# RK3399-AP register map
File version: 1
CPU: CA7 r0p1, little endian, MPU, FPU, I-cache, D-cache, VTOR, 4 interrupt priority bits, 0 interrupts
Registers are 32-bit, read-write, reset 0x0 unless marked. A register's access mark holds for its fields unless they carry their own. Offsets are from the block's base; [hi:lo] are bit positions; {n}, {i} and the like mark numbered series.

## EMMCCORE (part 1 of 2)
Base 0xFE330000
0x00 EMMCCORE_SADDR — System address/ Argument 2register/System address/ Argument 2 register
  [31:0] SADDR — This register contains the physical system memory address used for DMA transfers or the second argument for the Auto CMD23. (1) SDMA System Address This register contains the system memory address for a SDMA transfer. When the Host Controller stops a SDMA transfer, this register shall point to the system address of the next contiguous data position. It can be accessed only if no transaction is executing (i.e., after a transaction has stopped). Read operations during transfers may return an invalid value. The Host Driver shall initialize this register before starting a SDMA transaction. After SDMA has stopped, the next system address of the next contiguous data position can be read from this register. The SDMA transfer waits at the every boundary specified by the Host SDMA Buffer Boundary in the Block Size register. The Host Controller generates DMA Interrupt to request the Host Driver to update this register. The Host Driver sets the next system address of the next data position to this register. When the most upper byte of this register (003h) is written, the Host Controller restarts the SDMA transfer. When restarting SDMA by the Resume command or by setting Continue Request in the Block Gap Control register, the Host Controller shall start at the next contiguous address stored here in the SDMA System Address register. ADMA does not use this register. (2) Argument 2 This register is used with the Auto CMD23 to set a 32-bit block count value to the argument of the CMD23 while executing Auto CMD23. If Auto CMD23 is used with ADMA, the full 32-bit block count value can be used. If Auto CMD23 is used without AMDA, the available block count value is limited by the Block Count register. 65535 blocks is the maximum value in this case.
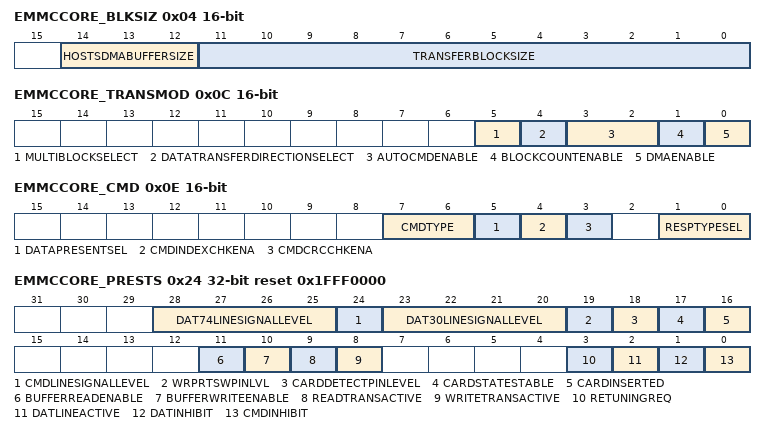
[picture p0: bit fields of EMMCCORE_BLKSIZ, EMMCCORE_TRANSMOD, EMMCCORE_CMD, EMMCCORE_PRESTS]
0x04 EMMCCORE_BLKSIZ 16-bit — Block size register
  [14:12] HOSTSDMABUFFERSIZE — To perform long DMA transfer, System Address register shall be updated at every system boundary during DMA transfer. These bits specify the size of contiguous buffer in the system memory. The DMA transfer shall wait at the every boundary specified by these fields and the HC generates the DMA Interrupt to request the HD to update the System Address register. These bits shall support when the DMA Support in the Capabilities register is set to 1 and this function is active when the DMA Enable in the Transfer Mode register is set to 1. 3\'h0: 4KB(Detects A11 Carry out) 3\'h1: 8KB(Detects A12 Carry out) 3\'h2: 16KB(Detects A13 Carry out) 3\'h3: 32KB(Detects A14 Carry out) 3\'h4: 64KB(Detects A15 Carry out) 3\'h5: 128KB(Detects A16 Carry out) 3\'h6: 256KB(Detects A17 Carry out) 3\'h7: 512KB(Detects A18 Carry out)
  [11:0] TRANSFERBLOCKSIZE — This register specifies the block size for block data transfers for CMD17, CMD18, CMD24, CMD25, and CMD53. It can be accessed only if no transaction is executing (i.e after a transaction has stopped). Read operations during transfer return an invalid value and write operations shall be ignored. 12\'h0000: No Data Transfer 12\'h0001: 1 Byte 12\'h0002: 2 Bytes 12\'h0003: 3 Bytes 12\'h0004: 4 Bytes ........ 12\'h01FF: 511 Bytes 12\'h0200: 512 Bytes ........ 12\'h0800: 2048 Bytes
0x06 EMMCCORE_BLKCNT 16-bit — Block count register
  [15:0] BLOCKCOUNTFORCURRENTTRANSFER — This register is enabled when Block Count Enable in the Transfer Mode register is set to 1 and is valid only for multiple block transfers. The HC decrements the block count after each block transfer and stops when the count reaches zero. It can be accessed only if no transaction is executing (i.e. after a transaction has stopped). Read operations during transfer return an invalid value and write operations shall be ignored. When saving transfer context as a result of Suspend command, the number of blocks yet to be transferred can be determined by reading this register. When restoring transfer context prior to issuing a Resume command, the HD shall restore the previously save block count. 16\'h0000: Stop Count 16\'h0001: 1 block 16\'h0002: 2 blocks ........ 16\'hFFFF: 65535 blocks
0x08 EMMCCORE_ARG — Argument register
  [31:0] COMMANDARGUMENT1 — The SD Command Argument is specified as bit39-8 of Command- Format.
0x0C EMMCCORE_TRANSMOD 16-bit — Transfer mode register
  [5] MULTIBLOCKSELECT — This bit enables multiple block data transfers. 0: Single Block 1: Multiple Block
  [4] DATATRANSFERDIRECTIONSELECT — This bit defines the direction of data transfers. 0: Write (Host to Card) 1: Read (Card to Host)
  [3:2] AUTOCMDENABLE — This field determines use of auto command functions 0: Auto Command Disabled 1: Auto CMD12 Enable 2: Auto CMD23 Enable 3: Reserved There are two methods to stop Multiple-block read and write operation. (1) Auto CMD12 Enable Multiple-block read and write commands for memory require CMD12 to stop the operation. When this field is set to 01b, the Host Controller issues CMD12 automatically when last block transferis completed. Auto CMD12 error is indicated to the Auto CMD Error Status register. The Host Driver shall not set this bit if the command does not require CMD12. (2) Auto CMD23 Enable When this bit field is set to 10b, the Host Controller issues a CMD23 automatically before issuing a command specified in the Command Register The following conditions are required to use the Auto CMD23. a. Auto CMD23 Supported (Host Controller Version is 3.00 or later) b. A memory card that supports CMD23 (SCR[33]=1) c. If DMA is used, it shall be ADMA d. Only when CMD18 or CMD25 is issued By writing the Command register, the Host Controller issues a CMD23 first and then issues a command specified by the Command Index in Command register 32-bit block count value for CMD23 is set to SDMA System Address / Argument 2 register
  [1] BLOCKCOUNTENABLE — This bit is used to enable the Block count register, which is only relevant for multiple block transfers. When this bit is 0, the Block Count register is disabled, which is useful in executing an infinite transfer. 0: Disable 1: Enable
  [0] DMAENABLE — DMA can be enabled only if DMA Support bit in the Capabilities register is set. If this bit is set to 1, a DMA operation shall begin when the HD writes to the upper byte of Command register (00Fh). 0: Disable 1: Enable
0x0E EMMCCORE_CMD 16-bit — Command register
  [7:6] CMDTYPE — 0: Normal 1: Suspend 2: Resume 3: Abort There are three types of special commands. Suspend, Resume and Abort. These bits shall bet set to 00b for all other commands. Suspend Command If the Suspend command succeeds, the HC shall assume the SD Bus has been released and that it is possible to issue the next command which uses the DAT line. The HC shall de-assert Read Wait for read transactions and stop checking busy for write transactions. The Interrupt cycle shall start, in 4-bit mode. If the Suspend command fails, the HC shall maintain its current state. and the HD shall restart the transfer by setting Continue Request in the Block Gap Control Register. Resume Command The HD re-starts the data transfer by restoring the registers in the range of 000-00Dh. The HC shall check for busy before starting write transfers. Abort Command If this command is set when executing a read transfer, the HC shall stop reads to the buffer. If this command is set when executing a write transfer, the HC shall stop driving the DAT line. After issuing the Abort command, the HD should issue a software reset.
  [5] DATAPRESENTSEL — 0: No Data Present 1: Data Present This bit is set to 1 to indicate that data is present and shall be transferred using the DAT line. If is set to 0 for the following: a. Commands using only CMD line (ex. CMD52) b. Commands with no data transfer but using busy signal on DAT[0] line (R1b or R5b ex. CMD38) c Resume Command
  [4] CMDINDEXCHKENA — If this bit is set to 1, the HC shall check the index field in the response to see if it has the same value as the command index. If it is not, it is reported as a Command Index Error. If this bit is set to 0, the Index field is not checked. 0: Disable 1: Enable
  [3] CMDCRCCHKENA — If this bit is set to 1, the HC shall check the CRC field in the response. If an error is detected, it is reported as a Command CRC Error. If this bit is set to 0, the CRC field is not checked. 0: Disable 1: Enable
  [1:0] RESPTYPESEL — Response Type Select 0: No Response 1: Response length 136 2: Response length 48 3: Response length 48 check Busy after response
{0x10+4i} EMMCCORE_RESP{i} (i=0..2) — Response register bit [{32i+31}:{32i}]
  [31:0] RESP
0x1C EMMCCORE_RESP3 — Response register bit [127:98]
  [31:0] RESP
0x20 EMMCCORE_BUFFER — Buffer data port register
  [31:0] BUFFERDATA — The Host Controller Buffer can be accessed through this 32-bit Data Port Register.
0x24 EMMCCORE_PRESTS access per field reset 0x1FFF0000 — Present state register
  [28:25] DAT74LINESIGNALLEVEL rw — This status is used to check DAT line level to recover from errors, and for debugging. [28]: DAT[7] [27]: DAT[6] [26]: DAT[5] [25]: DAT[4]
  [24] CMDLINESIGNALLEVEL ro — This status is used to check CMD line level to recover from errors, and for debugging.
  [23:20] DAT30LINESIGNALLEVEL ro — DAT[3:0] Line Signal Level This status is used to check DAT line level to recover from errors, and for debugging. This is especially useful in detecting the busy signal level from DAT[0]. [23]: DAT[3] [22]: DAT[2] [21]: DAT[1] [20]: DAT[0]
  [19] WRPRTSWPINLVL ro — Write Protect Switch Pin Level. The Write Protect Switch is supported for memory and combo cards. This bit reflects the SDWP# pin. 0: Write protected (SDWP# = 0) 1: Write enabled (SDWP# = 1)
  [18] CARDDETECTPINLEVEL ro — This bit reflects the inverse value of the SDCD# pin. 0: No Card present (SDCD# = 1) 1: Card present (SDCD# = 0)
  [17] CARDSTATESTABLE ro — 0: Reset of Debouncing 1: No Card or Inserted This bit is used for testing. If it is 0, the Card Detect Pin Level is not stable. If this bit is set to 1, it means the Card Detect Pin Level is stable. The Software Reset For All in the Software Reset Register shall not affect this bit.
  [16] CARDINSERTED ro — 0: Reset or Debouncing or NoCard 1: Card Inserted This bit indicates whether a card has been inserted. Changing from 0 to 1 generates a Card Insertion interrupt in the Normal Interrupt Status register and changing from 1 to 0 generates a Card Removal Interrupt in the Normal Interrupt Status register. The Software Reset For All in the Software Reset register shall not affect this bit. If a Card is removed while its power is on and its clock is oscillating, the HC shall clear SD Bus Power in the Power Control register and SD Clock Enable in the Clock control register. In addition the HD should clear the HC by the Software Reset For All in Software register. The card detect is active regardless of the SD Bus Power.
  [11] BUFFERREADENABLE ro — 0: Read Disable 1: Read Enable This status is used for non-DMA read transfers. This read only flag indicates that valid data exists in the host side buffer status. If this bit is 1, readable data exists in the buffer. A change of this bit from 1 to 0 occurs when all the block data is read from the buffer. A change of this bit from 0 to 1 occurs when all the block data is ready in the buffer and generates the Buffer Read Ready Interrupt.
  [10] BUFFERWRITEENABLE ro — 0: Write Disable 1: Write Enable This status is used for non-DMA write transfers. This read only flag indicates if space is available for write data. If this bit is 1, data can be written to the buffer. A change of this bit from 1 to 0 occurs when all the block data is written to the buffer. A change of this bit from 0 to 1 occurs when top of block data can be written to the buffer and generates the Buffer Write Ready Interrupt.
  [9] READTRANSACTIVE ro — 1: Transferring data 0: No valid data This status is used for detecting completion of a read transfer. This bit is set to 1 for either of the following conditions: a. After the end bit of the read command b. When writing a 1 to continue Request in the Block Gap Control register to restart a read transfer This bit is cleared to 0 for either of the following conditions: a. When the last data block as specified by block length is transferred to the system. b. When all valid data blocks have been transferred to the system and no current block transfers are being sent as a result of the Stop At Block Gap Request set to 1. A transfer complete interrupt is generated when this bit changes to 0.
  [8] WRITETRANSACTIVE ro — 1: transferring data 0: No valid data This status indicates a write transfer is active. If this bit is 0, it means no valid write data exists in the HC. This bit is set in either of the following cases: a. After the end bit of the write command. b. When writing a 1 to Continue Request in the Block Gap Control register to restart a write transfer. This bit is cleared in either of the following cases: a. After getting the CRC status of the last data block as specified by the transfer count (Single or Multiple). b. After getting a CRC status of any block where data transmission is about to be stopped by a Stop At Block Gap Request. During a write transaction, a Block Gap Event interrupt is generated when this bit is changed to 0, as a result of the Stop At Block Gap Request being set. This status is useful for the HD in determining when to issue commands during write busy.
  [3] RETUNINGREQ ro — Re-Tuning Request 1: Sampling clock needs re-tuning 0: Fixed or well tuned sampling clock Host Controller may request Host Driver to execute re-tuning sequence by setting this bit when the data window is shifted by temperature drift and a tuned sampling point does not have a good margin to receive correct data. This bit is cleared when a command is issued with setting Execute Tuning in the Host Control 2 register. Changing of this bit from 0 to 1 generates Re-Tuning Event. Refer to Normal Interrupt registers for more detail. This bit isn\'t set to 1 if Sampling Clock Select in the Host Control 2 register is set to 0 (using fixed sampling clock).
  [2] DATLINEACTIVE ro — This bit indicates whether one of the DAT line on SD bus is in use. 1: DAT line active 0: DAT line inactive
  [1] DATINHIBIT ro — 1: cannot issue command which uses the DAT line 0: Can issue command which uses the DAT line This status bit is generated if either the DAT Line Active or the Read transfer Active is set to 1. If this bit is 0, it indicates the HC can issue the next SD command. Commands with busy signal belong to Command Inhibit (DAT) (ex. R1b, R5b type). Changing from 1 to 0 generates a Transfer Complete interrupt in the Normal interrupt status register. Note: The SD Host Driver can save registers in the range of 000- 00Dh for a suspend transaction after this bit has changed from 1 to 0.
  [0] CMDINHIBIT ro — If this bit is 0, it indicates the CMD line is not in use and the HC can issue a SD command using the CMD line. This bit is set immediately after the Command register is written. This bit is cleared when the command response is received. Even if the Command Inhibit (DAT) is set to 1, Commands using only the CMD line can be issued if this bit is 0. Changing from 1 to 0 generates a Command complete interrupt in the Normal Interrupt Status register. If the HC cannot issue the command because of a command conflict error or because of Command Not Issued By Auto CMD12 Error, this bit shall remain 1 and the Command Complete is not set. Status issuing Auto CMD12 is not read from this bit. Auto CMD12 and Auto CMD23 consist of two responses. In this case, this bit is not cleared by the response of CMD12 or CMD23 but cleared by the response of a read/write command. Status issuing Auto CMD12 is not read from this bit. So if a command is issued during Auto CMD12 operation, Host Controller shall manage to issue two commands: CMD12 and a command set by Command register.
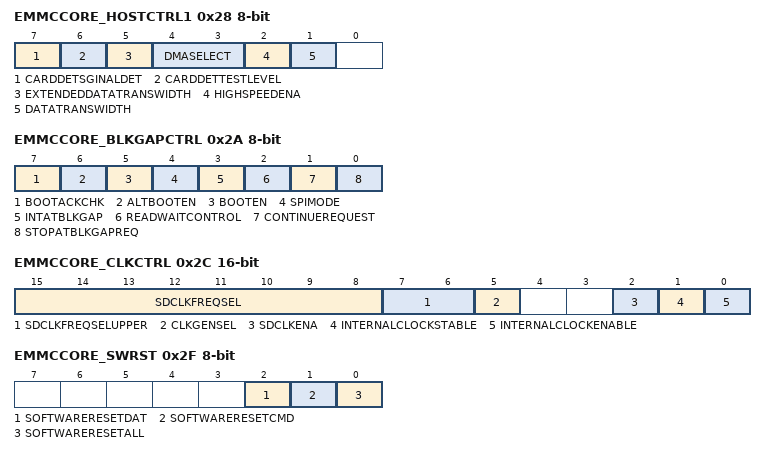
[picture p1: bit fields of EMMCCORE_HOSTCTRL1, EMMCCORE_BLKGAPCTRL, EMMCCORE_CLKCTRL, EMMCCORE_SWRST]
0x28 EMMCCORE_HOSTCTRL1 8-bit — Host control 1 register
  [7] CARDDETSGINALDET — This bit selects source for card detection. 1: The card detect test level is selected 0: SDCD# is selected (for normal use)
  [6] CARDDETTESTLEVEL — This bit is enabled while the Card Detect Signal Selection is set to 1 and it indicates card inserted or not. Generates (card ins or card removal) interrupt when the normal int sts enable bit is set. 1: Card Inserted 0: No Card
  [5] EXTENDEDDATATRANSWIDTH — This bit controls 8-bit bus width mode for embedded device. Support of this function is indicated in 8-bit Support for Embedded Device in the Capabilities register. If a device supports 8-bit bus mode, this bit may be set to 1. If this bit is 0, bus width is controlled by Data Transfer Width in the Host Control 1 register.This bit is not effective when multiple devices are installed on a bus slot (Slot Type is set to 10b in the Capabilities register). In this case, each device bus width is controlled by Bus Width Preset field in the Shared Bus register. 1: 8-bit Bus Width 0: Bus Width is Selected by Data Transfer Width
  [4:3] DMASELECT — One of supported DMA modes can be selected. The host driver shall check support of DMA modes by referring the Capabilities register. 0: SDMA is selected 1: 32-bit Address ADMA1 is selected 2: 32-bit Address ADMA2 is selected 3: 64-bit Address ADMA2 is selected
  [2] HIGHSPEEDENA — 1: High Speed Mode 0: Normal Speed Mode This bit is optional. Before setting this bit, the HD shall check the High Speed Support in the capabilities register. If this bit is set to 0 (default), the HC outputs CMD line and DAT lines at the falling edge of the SD clock (up to 25 MHz/20MHz for eMMC). If thisbit is set to 1, the HC outputs CMD line and DAT lines at the rising edge of the SD clock (up to 50 MHz for SD/52MHz for eMMC)/ 208Mhz (for SD3.0). If Preset Value Enable in the Host Control 2 register is set to 1, Host Driver needs to reset SD Clock Enable before changing this field to avoid generating clock glitches. After setting this field, the Host Driver sets SD Clock Enable again
  [1] DATATRANSWIDTH — 1: 4 bit mode 0: 1 bit mode This bit selects the data width of the HC. The HD shall select it to match the data width of the SD card.
0x29 EMMCCORE_PWRCTRL 8-bit — Power control register
  [0] SDBUSPOWER — 1: Power on 0: Power off
0x2A EMMCCORE_BLKGAPCTRL 8-bit access per field — Block gap control register
  [7] BOOTACKCHK rw — To check for the boot acknowledge in boot operation. 1: wait for boot ack from eMMC card 0: Will not wait for boot ack from eMMC card
  [6] ALTBOOTEN rw — To start boot code access in alternative mode. 1: To start alternate boot mode access 0: To stop alternate boot mode access
  [5] BOOTEN rw — To start boot code access. 1: To start boot code access 0: To stop boot code access
  [4] SPIMODE rw — SPI mode enable bit. 1: SPI mode 0: SD mode
  [3] INTATBLKGAP rw — Interrupt At Block Gap. This bit is valid only in 4-bit mode of the SDIO card and selects a sample point in the interrupt cycle. Setting to 1 enables interrupt detection at the block gap for a multiple block transfer. If the SD card cannot signal an interrupt during a multiple block transfer, this bit should be set to 0. When the HD detects an SD card insertion, it shall set this bit according to the CCCR of the SDIO card.
  [2] READWAITCONTROL rw — 1: Enable Read Wait Control 0: Disable Read Wait Control The read wait function is optional for SDIO cards. If the card supports read wait, set this bit to enable use of the read wait protocol to stop read data using DAT[2] line. Otherwise the HC has to stop the SD clock to hold read data, which restricts commands generation. When the HD detects an SD card insertion, it shall set this bit according to the CCCR of the SDIO card. If the card does not support read wait, this bit shall never be set to 1 otherwise DAT line conflict may occur. If this bit is set to 0, Suspend / Resume cannot be supported
  [1] CONTINUEREQUEST wo write-clears — 1: Restart 0: Ignored This bit is used to restart a transaction which was stopped using the Stop At Block Gap Request. To cancel stop at the block gap, set Stop At block Gap Request to 0 and set this bit to restart the transfer. The HC automatically clears this bit in either of the following cases: a. In the case of a read transaction, the DAT Line Active changes from 0 to 1 as a read transaction restarts. b. In the case of a write transaction, the Write transfer active changes from 0 to 1 as the write transaction restarts. Therefore it is not necessary for Host driver to set this bit to 0. If Stop At Block Gap Request is set to 1, any write to this bit is ignored.
  [0] STOPATBLKGAPREQ rw — 1: Stop 0: Transfer This bit is used to stop executing a transaction at the next block gap for non-DMA,SDMA and ADMA transfers. Until the transfer complete is set to 1, indicating a transfer completion the HD shall leave this bit set to 1. Clearing both the Stop At Block Gap Request and Continue Request shall not cause the transaction to restart. Read Wait is used to stop the read transaction at the block gap. The HC shall honour Stop At Block Gap Request for write transfers, but for read transfers it requires that the SD card support Read Wait. Therefore the HD shall not set this bit during read transfers unless the SD card supports Read Wait and has set Read Wait Control to 1. In case ofwrite transfers in which the HD writes data to the Buffer Data Port register, the HD shall set this bit after all block data is written. If this bit is set to 1, the HD shall not write data to Buffer data port register. This bit affects Read Transfer Active, Write Transfer Active, DAT line active and Command Inhibit (DAT) in the Present State register.
0x2C EMMCCORE_CLKCTRL 16-bit access per field — Clock control Register
  [15:8] SDCLKFREQSEL rw — SDCLK Frequency Select. This register is used to select the frequency of the SDCLK pin. The frequency is not programmed directly; rather this register holds the divisor of the Base Clock Frequency For SD clock in the capabilities register. Only the following settings are allowed. (1) 8-bit Divided Clock Mode 8\'h80: base clock divided by 256 8\'h40: base clock divided by 128 8\'h20: base clock divided by 64 8\'h10: base clock divided by 32 8\'h08: base clock divided by 16 8\'h04: base clock divided by 8 8\'h02: base clock divided by 4 8\'h01: base clock divided by 2 8\'h00: base clock(10MHz-63MHz) Setting 8\'h00 specifies the highest frequency of the SD Clock. When setting multiple bits, the most significant bit is used as the divisor. But multiple bits should not be set. The two default divider values can be calculated by the frequency that is defined by the Base Clock Frequency For SD Clock in the Capabilities register. a. 25 MHz divider value b. 400 KHz divider value The frequency of the SDCLK is set by the following formula: Clock Frequency = (Baseclock) / divisor. Thus choose the smallest possible divisor which results in a clock frequency that is less than or equal to the target frequency. Maximum Frequency for SD = 50Mhz (base clock) Maximum Frequency for eMMC = 52Mhz (base clock) Minimum Frequency = 195.3125Khz (50Mhz / 256), same calculation for eMMC also. (2) 10-bit Divided Clock Mode Host Controller supports this mandatory mode instead of the 8- bit Divided Clock Mode. The length of divider is extended to10 bits and all divider values shall be supported. 10\'h3FF:1/2046 Divided Clock N: 1/2N Divided Clock (Duty 50%) 10\'h002: 1/4 Divided Clock 10\'h001: 1/2 Divided Clock 10\'h000: Base Clock (10MHz-254MHz)
  [7:6] SDCLKFREQSELUPPER rw — Field0001 Abstract Upper Bits of SDCLK Frequency Select. Bit 07-06 is assigned to bit 09-08 of clock divider in SDCLK Frequency Select
  [5] CLKGENSEL rw — Clock Generator Select. 1: Programmable Clock Mode 0: Divided Clock Mode This bit is used to select the clock generator mode in SDCLK Frequency Select. If the Programmable Clock Mode is supported (non-zero value is set to Clock Multiplier in the Capabilities register), this bit attribute is RW, and if not supported, this bit attribute is RO and zero is read. This bit depends on the setting of Preset Value Enable in the Host Control 2 register. If the Preset Value Enable= 0, this bit is set by Host Driver. If the Preset Value Enable= 1, this bit is automatically set to a value specified in one of Preset Value registers.
  [2] SDCLKENA rw — SD Clock Enable. 1: Enable 0: Disable The HC shall stop SDCLK when writing this bit to 0. SDCLK frequency Select can be changed when this bit is 0. Then, the HC shall maintain the same clock frequency until SDCLK is stopped (Stop at SDCLK = 0). If the HC detects the No Card state, this bit shall be cleared.
  [1] INTERNALCLOCKSTABLE ro — Internal Clock Stable. 1: Ready 0: Not Ready This bit is set to 1 when SD clock is stable after writing to Internal Clock Enable in this register to 1. The SD Host Driver shall wait to set SD Clock Enable until this bit is set to 1. Note: This is useful when using PLL for a clock oscillator that requires setup time.
  [0] INTERNALCLOCKENABLE rw — 1: Oscillate 0: Stop This bit is set to 0 when the HD is not using the HC or the HC awaits a wakeup event. The HC should stop its internal clock to go very low power state. Still, registers shall be able to be read and written. Clock starts to oscillate when this bit is set to 1. When clock oscillation is stable, the HC shall set Internal Clock Stable in this register to 1. This bit shall not affect card detection.
0x2E EMMCCORE_TIMEOUT 8-bit — Timeout control register
  [3:0] DATATIMEOUTCOUNTERVALUE — This value determines the interval by which DAT line time-outs are detected. Refer to the Data Time-out Error in the Error Interrupt Statusregister for information on factors that dictate time-out generation. Time-out clock frequency will be generated by dividing the sdclockTMCLK by this value. When setting this register, prevent inadvertent time-out events by clearing the Data Time-out Error Status Enable (in the Error Interrupt Status Enable register). 4\'hf: Reserved 4\'he: TMCLK * 2^27 ...... 4\'h1: TMCLK * 2^14 4\'h0: TMCLK * 2^13
0x2F EMMCCORE_SWRST 8-bit wo — Software reset register
  [2] SOFTWARERESETDAT write-clears — Software Reset for DAT Line. 1: Reset 0: Work Only part of data circuit is reset. The following registers and bits are cleared by this bit: a. Buffer Data Port Register: Buffer is cleared and Initialized b. Present State register: Buffer read Enable Buffer write Enable Read Transfer Active Write Transfer Active DAT Line Active Command Inhibit (DAT) c. Block Gap Control register: Continue Request Stop At Block Gap Request d. Normal Interrupt Status register: Buffer Read Ready Buffer Write Ready Block Gap Event Transfer Complete
  [1] SOFTWARERESETCMD write-clears — Only part of command circuit is reset. 1: Reset 0: Work The following registers and bits are cleared by this bit: a. Present State register: Command Inhibit (CMD) b. Normal Interrupt Status register: Command Complete
  [0] SOFTWARERESETALL write-clears — Software Reset for All 1: Reset 0: Work This reset affects the entire HC except for the card detection circuit. Register bits of type ROC, RW, RW1C, RWAC are cleared to 0. During its initialization, the HD shall set this bit to 1 to reset the HC. The HC shall reset this bit to 0 when capabilities registers are valid and the HD can read them. Additional use of Software Reset For All may not affect the value of the Capabilities registers. If this bit is set to 1, the SD card shall reset itself and must be reinitialized by the HD.
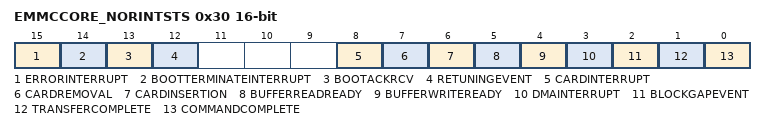
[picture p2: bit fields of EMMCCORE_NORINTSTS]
0x30 EMMCCORE_NORINTSTS 16-bit access per field — Normal interrupt status register
  [15] ERRORINTERRUPT ro — 0: No Error 1: Error If any of the bits inthe Error Interrupt Status Register are set, then this bit is set. Therefore the HD can test for an error by checking this bit first.
  [14] BOOTTERMINATEINTERRUPT rw write-1-clears — This status is set if the boot operation get terminated 0: Boot operation is not terminated 1: Boot operation is terminated
  [13] BOOTACKRCV rw write-1-clears — This status is set if the boot acknowledge is received from device. 0: Boot ack is not received 1: Boot ack is received
  [12] RETUNINGEVENT ro — 1: Re-Tuning should be performed 0: Re-Tuning is not required This status is set if Re-Tuning Request in the Present State register changes from 0 to 1. Host Controller requestsHost Driver to perform re-tuning for next data transfer. Current data transfer (not large block count) can be completed without re-tuning.
  [8] CARDINTERRUPT ro — 0: No Card Interrupt 1: Generate Card Interrupt Writing this bit to 1 does not clear this bit. It is cleared by resetting the SD card interrupt factor. In 1-bit mode, the HC shall detect the Card Interrupt without SD Clock to support wakeup. In 4-bit mode, the card interrupt signal is sampled during the interrupt cycle, so there are some sample delays between the interrupt signal from the card and the interrupt to the Host system. when this status has been set and the HD needs to start this interrupt service, Card Interrupt Status Enable in the Normal Interrupt Status register shall be set to 0 in order to clear the card interrupt statuses latched in the HC and stop driving the Host System. After completion of the card interrupt service (the reset factor in the SD card and the interrupt signal may not be asserted), set Card Interrupt Status Enable to 1 and start sampling the interrupt signal again. Interrupt detected by DAT[1] is supported when there is a card per slot.
  [7] CARDREMOVAL rw write-1-clears — 0: Card State Stable or Debouncing 1: Card Removed This status is set if the Card Inserted in the Present State register changes from 1 to 0. When the HD writes this bit to 1 to clear this status the status of the Card Inserted in the Present State registershould be confirmed. Because the card detect may possibly be changed when the HD clear this bit an Interrupt event may not be generated.
  [6] CARDINSERTION rw write-1-clears — 0: Card State Stable or Debouncing 1: Card Inserted This status is set if the Card Inserted in the Present State register changes from 0 to 1. When the HD writes this bit to 1 to clear this status the status of the Card Inserted in the Present State registershould be confirmed. Because the card detect may possibly be changed when the HD clear this bit an Interrupt event may not be generated.
  [5] BUFFERREADREADY rw write-1-clears — 0: Not Ready to read Buffer 1: Ready to read Buffer This status is set if the Buffer Read Enable changes from 0 to 1. Buffer Read Ready is set to 1 for every CMD19 execution in tuning procedure.
  [4] BUFFERWRITEREADY rw write-1-clears — 0: Not Ready to Write Buffer 1: Ready to Write Buffer This status is set if the Buffer Write Enable changes from 0 to 1.
  [3] DMAINTERRUPT rw write-1-clears — 0: No DMA Interrupt 1: DMA Interrupt is Generated This status is set if the HC detects the Host DMA Buffer Boundary in the Block Size regiser.
  [2] BLOCKGAPEVENT rw write-1-clears — 0: No Block Gap Event 1: Transaction stopped at Block Gap If the Stop At Block Gap Request in the Block Gap Control Register is set, this bit is set. a. Read Transaction: This bit is set at the falling edge of the DAT Line Active Status (When the transaction is stopped at SD Bus timing. The Read Wait must be supported inorder to use this function). b. Write Transaction: This bit is set at the falling edge of Write Transfer Active Status (After getting CRC status at SD Bus timing).
  [1] TRANSFERCOMPLETE rw write-1-clears — 0: No Data Transfer Complete 1: Data Transfer Complete This bit is set when a read / write transaction is completed. a. Read Transaction: This bit is set at the falling edge of Read Transfer Active Status. There are two cases in which the Interrupt is generated. The first is when a data transfer is completed as specified by data length (After the last data has been read to the Host System). The second is when data has stopped at the block gap and completed the data transfer by setting the Stop At Block Gap Request in the Block Gap Control Register (After valid data has been read to the Host System). b. Write Transaction: This bit is set at the falling edge of the DAT Line Active Status. There are two cases in which the Interrupt is generated. The first is when the last data is written to the card as specified by data length and Busy signal is released. The second is when data transfers are stopped at the block gap by setting Stop At Block Gap Request in the Block Gap Control Register and data transfers completed. (Aftervalid data is written to the SD card and the busy signal is released). c. In case of command with busy This bit is set when busy is deasserted. Note: a. Transfer Complete has higher priority than Data Time-out Error. If both bits are set to 1, the data transfer can be considered complete b. While performing tuning procedure (Execute Tuning is set to 1), Transfer Complete is not set to 1
  [0] COMMANDCOMPLETE rw write-1-clears — 0: No Command Complete 1: Command Complete This bit is set when we get the end bit of the command response (Except Auto CMD12 and Auto CMD23) Note: Command Time-out Error has higher priority than Command Complete. If both are set to 1, it can be considered that the response was not received correctly.
